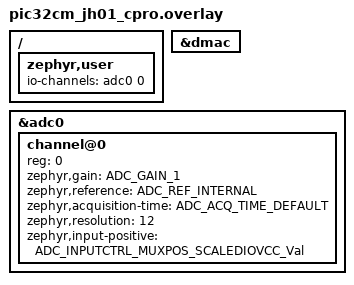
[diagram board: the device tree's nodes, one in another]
/*
 * Copyright (c) 2026 Microchip Technology Inc.
 *
 * SPDX-License-Identifier: Apache-2.0
 */

tst_dma0: &dmac {
	status = "okay";
};

#define ADC_INPUTCTRL_MUXPOS_SCALEDIOVCC_Val 0x1BU

/ {
	zephyr,user {
		io-channels = <&adc0 0>;
	};
};

&adc0 {
	#address-cells = <1>;
	#size-cells = <0>;
	status = "okay";
	channel@0 {
		reg = <0>;
		zephyr,gain = "ADC_GAIN_1";
		zephyr,reference = "ADC_REF_INTERNAL";
		zephyr,acquisition-time = <ADC_ACQ_TIME_DEFAULT>;
		zephyr,resolution = <12>;
		zephyr,input-positive = <ADC_INPUTCTRL_MUXPOS_SCALEDIOVCC_Val>;
	};
};
